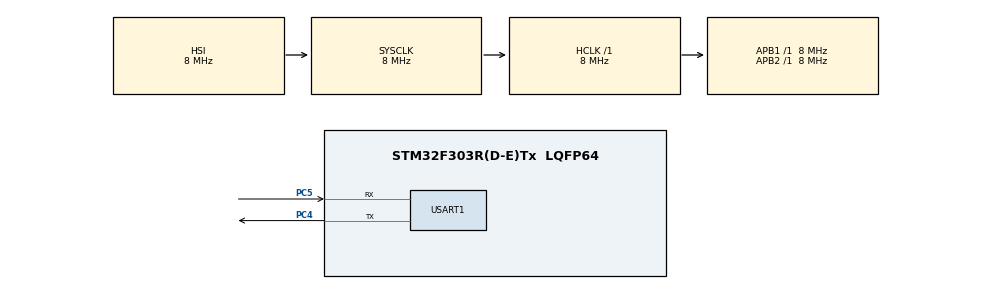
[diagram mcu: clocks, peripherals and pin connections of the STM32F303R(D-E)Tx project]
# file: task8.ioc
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ADC1.Channel-0\#ChannelRegularConversion=ADC_CHANNEL_VREFINT
ADC1.Channel-2\#ChannelRegularConversion=ADC_CHANNEL_TEMPSENSOR
ADC1.ContinuousConvMode=ENABLE
ADC1.EOCSelection=ADC_EOC_SINGLE_CONV
ADC1.NbrOfConversion=2
ADC1.NbrOfConversionFlag=1
ADC1.Offset-0\#ChannelRegularConversion=0
ADC1.Offset-2\#ChannelRegularConversion=0
ADC1.OffsetNumber-0\#ChannelRegularConversion=ADC_OFFSET_NONE
ADC1.OffsetNumber-2\#ChannelRegularConversion=ADC_OFFSET_NONE
ADC1.Rank-0\#ChannelRegularConversion=1
ADC1.Rank-2\#ChannelRegularConversion=2
ADC1.SamplingTime-0\#ChannelRegularConversion=ADC_SAMPLETIME_601CYCLES_5
ADC1.SamplingTime-2\#ChannelRegularConversion=ADC_SAMPLETIME_601CYCLES_5
ADC1.SamplingTimeOPAMP-2\#ChannelRegularConversion=ADC_SAMPLETIME_4CYCLES_5
ADC1.master=1
Dma.ADC1.0.Direction=DMA_PERIPH_TO_MEMORY
Dma.ADC1.0.Instance=DMA1_Channel1
Dma.ADC1.0.MemDataAlignment=DMA_MDATAALIGN_HALFWORD
Dma.ADC1.0.MemInc=DMA_MINC_ENABLE
Dma.ADC1.0.Mode=DMA_CIRCULAR
Dma.ADC1.0.PeriphDataAlignment=DMA_PDATAALIGN_HALFWORD
Dma.ADC1.0.PeriphInc=DMA_PINC_DISABLE
Dma.ADC1.0.Priority=DMA_PRIORITY_LOW
Dma.Request0=ADC1
Dma.Request1=USART1_TX
Dma.USART1_TX.1.Direction=DMA_MEMORY_TO_PERIPH
Dma.USART1_TX.1.Instance=DMA1_Channel4
Dma.USART1_TX.1.MemDataAlignment=DMA_MDATAALIGN_BYTE
Dma.USART1_TX.1.MemInc=DMA_MINC_ENABLE
Dma.USART1_TX.1.Mode=DMA_NORMAL
Dma.USART1_TX.1.PeriphDataAlignment=DMA_PDATAALIGN_BYTE
Dma.USART1_TX.1.PeriphInc=DMA_PINC_DISABLE
Dma.USART1_TX.1.Priority=DMA_PRIORITY_LOW
FREERTOS.Tasks01=Task1,24,128,TaskFunction1,Default,NULL,Dynamic,NULL,NULL
FREERTOS.configUSE_NEWLIB_REENTRANT=0
Mcu.Family=STM32F3
Mcu.Name=STM32F303R(D-E)Tx
Mcu.Package=LQFP64
NVIC.ADC1_2_IRQn=true\:5\:0\:false\:false\:true\:true\:true\:true\:true
NVIC.DMA1_Channel1_IRQn=true\:5\:0\:false\:false\:true\:true\:false\:true\:true
NVIC.DMA1_Channel4_IRQn=true\:5\:0\:false\:false\:true\:true\:false\:true\:true
NVIC.PriorityGroup=NVIC_PRIORITYGROUP_4
NVIC.TIM7_IRQn=true\:15\:0\:false\:false\:true\:false\:false\:true\:true
NVIC.TimeBase=TIM7_IRQn
NVIC.TimeBaseIP=TIM7
NVIC.USART1_IRQn=true\:5\:0\:false\:false\:true\:true\:true\:true\:true
PA13.Mode=Serial_Wire
PA13.Signal=SYS_JTMS-SWDIO
PA14.Mode=Serial_Wire
PA14.Signal=SYS_JTCK-SWCLK
PB3.Signal=SYS_JTDO-TRACESWO
PC14-OSC32_IN.Mode=LSE-External-Oscillator
PC14-OSC32_IN.Signal=RCC_OSC32_IN
PC15-OSC32_OUT.Mode=LSE-External-Oscillator
PC15-OSC32_OUT.Signal=RCC_OSC32_OUT
PC4.Mode=Asynchronous
PC4.Signal=USART1_TX
PC5.Mode=Asynchronous
PC5.Signal=USART1_RX
PF0-OSC_IN.Mode=HSE-External-Oscillator
PF0-OSC_IN.Signal=RCC_OSC_IN
PF1-OSC_OUT.Mode=HSE-External-Oscillator
PF1-OSC_OUT.Signal=RCC_OSC_OUT
ProjectManager.HeapSize=0x200
ProjectManager.StackSize=0x400
ProjectManager.TargetToolchain=STM32CubeIDE
RCC.AHBFreq_Value=8000000
RCC.APB1Freq_Value=8000000
RCC.APB2Freq_Value=8000000
RCC.CortexFreq_Value=8000000
RCC.HSE_VALUE=8000000
RCC.HSI_VALUE=8000000
RCC.PLLMUL=RCC_PLL_MUL4
RCC.SYSCLKFreq_VALUE=8000000
RCC.USBFreq_Value=16000000
USART1.VirtualMode-Asynchronous=VM_ASYNC
VP_ADC1_TempSens_Input.Mode=IN-TempSens
VP_ADC1_Vref_Input.Mode=IN-Vrefint
VP_FREERTOS_VS_CMSIS_V2.Mode=CMSIS_V2
VP_SYS_VS_tim7.Mode=TIM7
board=custom

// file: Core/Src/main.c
/* USER CODE BEGIN Header */
/**
  ******************************************************************************
  * @file           : main.c
  * @brief          : Main program body
  ******************************************************************************
  * @attention
  *
  * Copyright (c) 2025 STMicroelectronics.
  * All rights reserved.
  *
  * This software is licensed under terms that can be found in the LICENSE file
  * in the root directory of this software component.
  * If no LICENSE file comes with this software, it is provided AS-IS.
  *
  ******************************************************************************
  */
/* USER CODE END Header */
#include "main.h"
#include "cmsis_os.h"
#include "adc.h"
#include "dma.h"
#include "usart.h"
#include "gpio.h"

/* USER CODE BEGIN Includes */
#include "task.h"
#include "adcTask.h"
#include "smf.h"
#include "core_cm4.h"
/* USER CODE END Includes */

/* USER CODE BEGIN PD */
//  #define VREFINT_CAL_ADDR ((uint16_t*) ((uint32_t)0x1FFFF7BAU))
/* USER CODE END PD */

/* USER CODE BEGIN PV */

//  uint32_t adcValue;
//  uint32_t value;
//    static uint16_t Vref_cal=0;
//  uint32_t adc_Vref;
//  uint32_t raw;
//  float voltaj;
//  float temp, Vref;

/* USER CODE END PV */

void SystemClock_Config(void);
void MX_FREERTOS_Init(void);
/* USER CODE BEGIN PFP */
void TaskFunction2(void *argument);
void TaskFunction3(void *argumnet);
/* USER CODE END PFP */

/* USER CODE BEGIN 0 */
int __io_putchar(int ch) {
	    ITM_SendChar('A');
	    return ch;
	}
/* USER CODE END 0 */

int main(void)
{

  /* MCU Configuration--------------------------------------------------------*/

  /* Reset of all peripherals, Initializes the Flash interface and the Systick. */
  HAL_Init();

  /* Configure the system clock */
  SystemClock_Config();

  /* Initialize all configured peripherals */
  MX_GPIO_Init();
  MX_DMA_Init();
  MX_ADC1_Init();
  MX_USART1_UART_Init();

  /* Init scheduler */
  osKernelInitialize();  /* Call init function for freertos objects (in cmsis_os2.c) */
  MX_FREERTOS_Init();

  /* Start scheduler */
  osKernelStart();

  /* We should never get here as control is now taken by the scheduler */

  /* Infinite loop */
  while (1)
  {

  }
}

void SystemClock_Config(void)
{
  RCC_OscInitTypeDef RCC_OscInitStruct = {0};
  RCC_ClkInitTypeDef RCC_ClkInitStruct = {0};
  RCC_PeriphCLKInitTypeDef PeriphClkInit = {0};

  /** Initializes the RCC Oscillators according to the specified parameters
  * in the RCC_OscInitTypeDef structure.
  */
  RCC_OscInitStruct.OscillatorType = RCC_OSCILLATORTYPE_HSI;
  RCC_OscInitStruct.HSIState = RCC_HSI_ON;
  RCC_OscInitStruct.HSICalibrationValue = RCC_HSICALIBRATION_DEFAULT;
  RCC_OscInitStruct.PLL.PLLState = RCC_PLL_ON;
  RCC_OscInitStruct.PLL.PLLSource = RCC_PLLSOURCE_HSI;
  RCC_OscInitStruct.PLL.PLLMUL = RCC_PLL_MUL4;
  RCC_OscInitStruct.PLL.PREDIV = RCC_PREDIV_DIV1;
  if (HAL_RCC_OscConfig(&RCC_OscInitStruct) != HAL_OK)
  {
    Error_Handler();
  }

  /** Initializes the CPU, AHB and APB buses clocks
  */
  RCC_ClkInitStruct.ClockType = RCC_CLOCKTYPE_HCLK|RCC_CLOCKTYPE_SYSCLK
                              |RCC_CLOCKTYPE_PCLK1|RCC_CLOCKTYPE_PCLK2;
  RCC_ClkInitStruct.SYSCLKSource = RCC_SYSCLKSOURCE_HSI;
  RCC_ClkInitStruct.AHBCLKDivider = RCC_SYSCLK_DIV1;
  RCC_ClkInitStruct.APB1CLKDivider = RCC_HCLK_DIV1;
  RCC_ClkInitStruct.APB2CLKDivider = RCC_HCLK_DIV1;

  if (HAL_RCC_ClockConfig(&RCC_ClkInitStruct, FLASH_LATENCY_0) != HAL_OK)
  {
    Error_Handler();
  }
  PeriphClkInit.PeriphClockSelection = RCC_PERIPHCLK_USART1|RCC_PERIPHCLK_ADC12;
  PeriphClkInit.Usart1ClockSelection = RCC_USART1CLKSOURCE_PCLK2;
  PeriphClkInit.Adc12ClockSelection = RCC_ADC12PLLCLK_DIV1;
  if (HAL_RCCEx_PeriphCLKConfig(&PeriphClkInit) != HAL_OK)
  {
    Error_Handler();
  }
}

void HAL_TIM_PeriodElapsedCallback(TIM_HandleTypeDef *htim)
{
  if (htim->Instance == TIM7)
  {
    HAL_IncTick();
  }
}

void Error_Handler(void)
{
  __disable_irq();
  while (1)
  {
  }
}

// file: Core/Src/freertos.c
/* USER CODE BEGIN Header */
/**
  ******************************************************************************
  * File Name          : freertos.c
  * Description        : Code for freertos applications
  ******************************************************************************
  * @attention
  *
  * Copyright (c) 2025 STMicroelectronics.
  * All rights reserved.
  *
  * This software is licensed under terms that can be found in the LICENSE file
  * in the root directory of this software component.
  * If no LICENSE file comes with this software, it is provided AS-IS.
  *
  ******************************************************************************
  */
/* USER CODE END Header */

#include "FreeRTOS.h"
#include "task.h"
#include "main.h"
#include "cmsis_os.h"

/* Definitions for Task1 */
osThreadId_t Task1Handle;
const osThreadAttr_t Task1_attributes = {
  .name = "Task1",
  .stack_size = 128 * 4,
  .priority = (osPriority_t) osPriorityNormal,
};

/* USER CODE BEGIN FunctionPrototypes */
osThreadId_t Task2Handle;
const osThreadAttr_t Task2_attributes = {
  .name = "Task2",
  .stack_size = 128 * 4,
  .priority = (osPriority_t) osPriorityNormal,
};
/* USER CODE END FunctionPrototypes */

void TaskFunction1(void *argument);

void MX_FREERTOS_Init(void); /* (MISRA C 2004 rule 8.1) */

void MX_FREERTOS_Init(void) {
  /* USER CODE BEGIN Init */
void TaskFunction2(void *argument);
  /* USER CODE END Init */

  /* Create the thread(s) */
  /* creation of Task1 */
  Task1Handle = osThreadNew(TaskFunction1, NULL, &Task1_attributes);

  /* USER CODE BEGIN RTOS_THREADS */
  // TODO: Create task here
  Task2Handle = osThreadNew(TaskFunction2, NULL, &Task2_attributes);
  /* add threads, ... */
  /* USER CODE END RTOS_THREADS */

}

void TaskFunction1(void *argument)
{
  for(;;)
  {
    osDelay(1);
  }
}
